# S32K148 register map
Vendor: NXP; Series: S32K; File version: 1.6
CPU: CM4 r0p1, little endian, MPU, FPU, 4 interrupt priority bits
Registers are 32-bit, read-write, reset 0x0 unless marked. A register's access mark holds for its fields unless they carry their own. Offsets are from the block's base; [hi:lo] are bit positions; {n}, {i} and the like mark numbered series; 'fields as' and 'values as' point back to an identical list.

## AIPS — AIPS-Lite Bridge
Base 0x40000000; register names take the prefix AIPS_
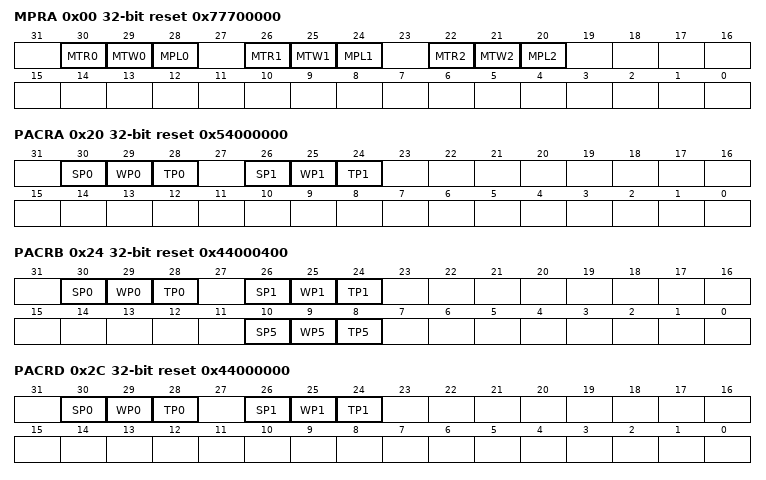
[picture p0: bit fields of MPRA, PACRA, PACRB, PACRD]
0x00 MPRA reset 0x77700000 — Master Privilege Register A
  [30] MTR0 — Master 0 Trusted For Read
    0=This master is not trusted for read accesses; 1=This master is trusted for read accesses
  [29] MTW0 — Master 0 Trusted For Writes
    0=This master is not trusted for write accesses; 1=This master is trusted for write accesses
  [28] MPL0 — Master 0 Privilege Level
    0=Accesses from this master are forced to user-mode; 1=Accesses from this master are not forced to user-mode
  [26] MTR1 — Master 1 Trusted for Read
    values as MTR0
  [25] MTW1 — Master 1 Trusted for Writes
    values as MTW0
  [24] MPL1 — Master 1 Privilege Level
    values as MPL0
  [22] MTR2 — Master 2 Trusted For Read
    values as MTR0
  [21] MTW2 — Master 2 Trusted For Writes
    values as MTW0
  [20] MPL2 — Master 2 Privilege Level
    values as MPL0
0x20 PACRA reset 0x54000000 — Peripheral Access Control Register
  [30] SP0 — Supervisor Protect
    0=This peripheral does not require supervisor privilege level for accesses; 1=This peripheral requires supervisor privilege level for accesses
  [29] WP0 — Write Protect
    0=This peripheral allows write accesses; 1=This peripheral is write protected
  [28] TP0 — Trusted Protect
    0=Accesses from an untrusted master are allowed; 1=Accesses from an untrusted master are not allowed
  [26] SP1 — Supervisor Protect
    values as SP0
  [25] WP1 — Write Protect
    values as WP0
  [24] TP1 — Trusted Protect
    values as TP0
0x24 PACRB reset 0x44000400 — Peripheral Access Control Register
  [30] SP0 — Supervisor Protect
    values as PACRA.SP0
  [29] WP0 — Write Protect
    values as PACRA.WP0
  [28] TP0 — Trusted Protect
    values as PACRA.TP0
  [26] SP1 — Supervisor Protect
    values as PACRA.SP0
  [25] WP1 — Write Protect
    values as PACRA.WP0
  [24] TP1 — Trusted Protect
    values as PACRA.TP0
  [10] SP5 — Supervisor Protect
    values as PACRA.SP0
  [9] WP5 — Write Protect
    values as PACRA.WP0
  [8] TP5 — Trusted Protect
    values as PACRA.TP0
0x28 PACRC ro — Peripheral Access Control Register
0x2C PACRD reset 0x44000000 — Peripheral Access Control Register
  fields as PACRA
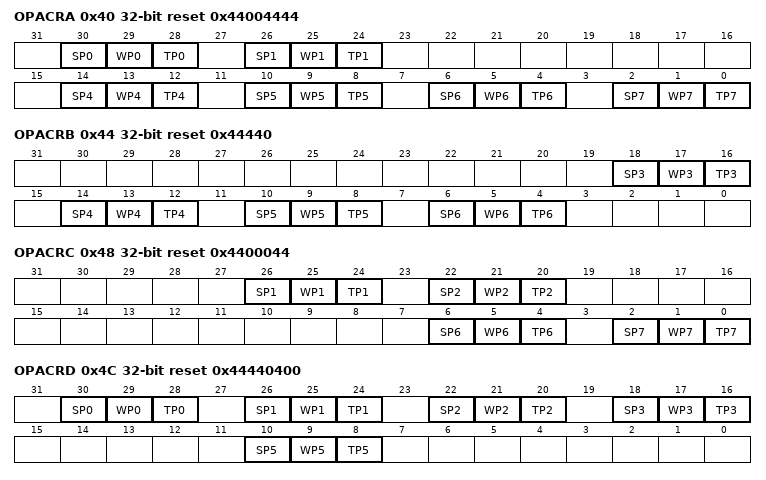
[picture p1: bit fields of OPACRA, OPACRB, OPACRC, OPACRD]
0x40 OPACRA reset 0x44004444 — Off-Platform Peripheral Access Control Register
  [30] SP0 — Supervisor Protect
    values as PACRA.SP0
  [29] WP0 — Write Protect
    values as PACRA.WP0
  [28] TP0 — Trusted Protect
    values as PACRA.TP0
  [26] SP1 — Supervisor Protect
    values as PACRA.SP0
  [25] WP1 — Write Protect
    values as PACRA.WP0
  [24] TP1 — Trusted Protect
    values as PACRA.TP0
  [30-4n] SP{n} (n=4..7) — Supervisor Protect
    values as PACRA.SP0
  [29-4n] WP{n} (n=4..7) — Write Protect
    values as PACRA.WP0
  [28-4n] TP{n} (n=4..7) — Trusted Protect
    values as PACRA.TP0
0x44 OPACRB reset 0x44440 — Off-Platform Peripheral Access Control Register
  [30-4n] SP{n} (n=3..6) — Supervisor Protect
    values as PACRA.SP0
  [29-4n] WP{n} (n=3..6) — Write Protect
    values as PACRA.WP0
  [28-4n] TP{n} (n=3..6) — Trusted Protect
    values as PACRA.TP0
0x48 OPACRC reset 0x4400044 — Off-Platform Peripheral Access Control Register
  [26] SP1 — Supervisor Protect
    values as PACRA.SP0
  [25] WP1 — Write Protect
    values as PACRA.WP0
  [24] TP1 — Trusted Protect
    values as PACRA.TP0
  [22] SP2 — Supervisor Protect
    values as PACRA.SP0
  [21] WP2 — Write Protect
    values as PACRA.WP0
  [20] TP2 — Trusted Protect
    values as PACRA.TP0
  [6] SP6 — Supervisor Protect
    values as PACRA.SP0
  [5] WP6 — Write Protect
    values as PACRA.WP0
  [4] TP6 — Trusted Protect
    values as PACRA.TP0
  [2] SP7 — Supervisor Protect
    values as PACRA.SP0
  [1] WP7 — Write Protect
    values as PACRA.WP0
  [0] TP7 — Trusted Protect
    values as PACRA.TP0
0x4C OPACRD reset 0x44440400 — Off-Platform Peripheral Access Control Register
  [30-4n] SP{n} (n=0..3) — Supervisor Protect
    values as PACRA.SP0
  [29-4n] WP{n} (n=0..3) — Write Protect
    values as PACRA.WP0
  [28-4n] TP{n} (n=0..3) — Trusted Protect
    values as PACRA.TP0
  [10] SP5 — Supervisor Protect
    values as PACRA.SP0
  [9] WP5 — Write Protect
    values as PACRA.WP0
  [8] TP5 — Trusted Protect
    values as PACRA.TP0
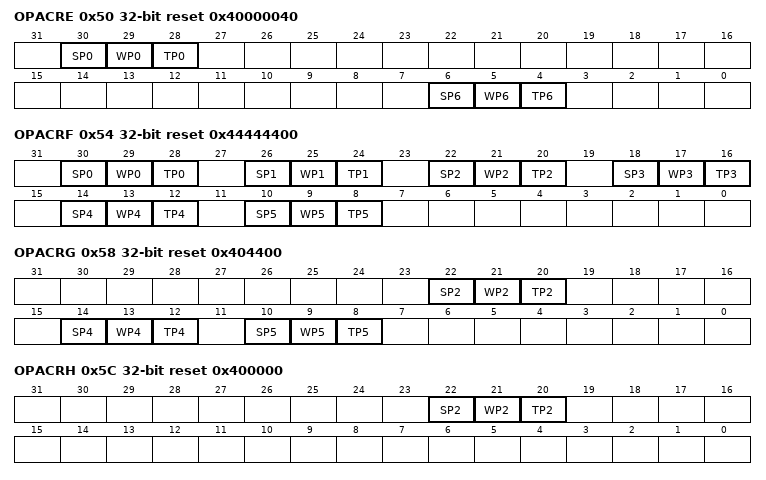
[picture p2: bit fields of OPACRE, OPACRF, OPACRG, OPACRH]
0x50 OPACRE reset 0x40000040 — Off-Platform Peripheral Access Control Register
  [30] SP0 — Supervisor Protect
    values as PACRA.SP0
  [29] WP0 — Write Protect
    values as PACRA.WP0
  [28] TP0 — Trusted Protect
    values as PACRA.TP0
  [6] SP6 — Supervisor Protect
    values as PACRA.SP0
  [5] WP6 — Write Protect
    values as PACRA.WP0
  [4] TP6 — Trusted Protect
    values as PACRA.TP0
0x54 OPACRF reset 0x44444400 — Off-Platform Peripheral Access Control Register
  [30-4n] SP{n} (n=0..5) — Supervisor Protect
    values as PACRA.SP0
  [29-4n] WP{n} (n=0..5) — Write Protect
    values as PACRA.WP0
  [28-4n] TP{n} (n=0..5) — Trusted Protect
    values as PACRA.TP0
0x58 OPACRG reset 0x404400 — Off-Platform Peripheral Access Control Register
  [22] SP2 — Supervisor Protect
    values as PACRA.SP0
  [21] WP2 — Write Protect
    values as PACRA.WP0
  [20] TP2 — Trusted Protect
    values as PACRA.TP0
  [14] SP4 — Supervisor Protect
    values as PACRA.SP0
  [13] WP4 — Write Protect
    values as PACRA.WP0
  [12] TP4 — Trusted Protect
    values as PACRA.TP0
  [10] SP5 — Supervisor Protect
    values as PACRA.SP0
  [9] WP5 — Write Protect
    values as PACRA.WP0
  [8] TP5 — Trusted Protect
    values as PACRA.TP0
0x5C OPACRH reset 0x400000 — Off-Platform Peripheral Access Control Register
  [22] SP2 — Supervisor Protect
    values as PACRA.SP0
  [21] WP2 — Write Protect
    values as PACRA.WP0
  [20] TP2 — Trusted Protect
    values as PACRA.TP0
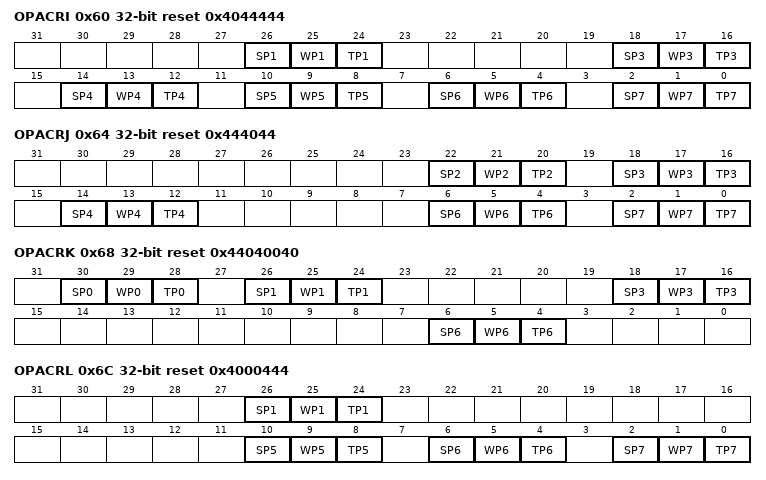
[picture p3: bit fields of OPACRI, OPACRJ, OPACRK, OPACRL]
0x60 OPACRI reset 0x4044444 — Off-Platform Peripheral Access Control Register
  [26] SP1 — Supervisor Protect
    values as PACRA.SP0
  [25] WP1 — Write Protect
    values as PACRA.WP0
  [24] TP1 — Trusted Protect
    values as PACRA.TP0
  [30-4n] SP{n} (n=3..7) — Supervisor Protect
    values as PACRA.SP0
  [29-4n] WP{n} (n=3..7) — Write Protect
    values as PACRA.WP0
  [28-4n] TP{n} (n=3..7) — Trusted Protect
    values as PACRA.TP0
0x64 OPACRJ reset 0x444044 — Off-Platform Peripheral Access Control Register
  [22] SP2 — Supervisor Protect
    values as PACRA.SP0
  [21] WP2 — Write Protect
    values as PACRA.WP0
  [20] TP2 — Trusted Protect
    values as PACRA.TP0
  [18] SP3 — Supervisor Protect
    values as PACRA.SP0
  [17] WP3 — Write Protect
    values as PACRA.WP0
  [16] TP3 — Trusted Protect
    values as PACRA.TP0
  [14] SP4 — Supervisor Protect
    values as PACRA.SP0
  [13] WP4 — Write Protect
    values as PACRA.WP0
  [12] TP4 — Trusted Protect
    values as PACRA.TP0
  [6] SP6 — Supervisor Protect
    values as PACRA.SP0
  [5] WP6 — Write Protect
    values as PACRA.WP0
  [4] TP6 — Trusted Protect
    values as PACRA.TP0
  [2] SP7 — Supervisor Protect
    values as PACRA.SP0
  [1] WP7 — Write Protect
    values as PACRA.WP0
  [0] TP7 — Trusted Protect
    values as PACRA.TP0
0x68 OPACRK reset 0x44040040 — Off-Platform Peripheral Access Control Register
  [30] SP0 — Supervisor Protect
    values as PACRA.SP0
  [29] WP0 — Write Protect
    values as PACRA.WP0
  [28] TP0 — Trusted Protect
    values as PACRA.TP0
  [26] SP1 — Supervisor Protect
    values as PACRA.SP0
  [25] WP1 — Write Protect
    values as PACRA.WP0
  [24] TP1 — Trusted Protect
    values as PACRA.TP0
  [18] SP3 — Supervisor Protect
    values as PACRA.SP0
  [17] WP3 — Write Protect
    values as PACRA.WP0
  [16] TP3 — Trusted Protect
    values as PACRA.TP0
  [6] SP6 — Supervisor Protect
    values as PACRA.SP0
  [5] WP6 — Write Protect
    values as PACRA.WP0
  [4] TP6 — Trusted Protect
    values as PACRA.TP0
0x6C OPACRL reset 0x4000444 — Off-Platform Peripheral Access Control Register
  [26] SP1 — Supervisor Protect
    values as PACRA.SP0
  [25] WP1 — Write Protect
    values as PACRA.WP0
  [24] TP1 — Trusted Protect
    values as PACRA.TP0
  [10] SP5 — Supervisor Protect
    values as PACRA.SP0
  [9] WP5 — Write Protect
    values as PACRA.WP0
  [8] TP5 — Trusted Protect
    values as PACRA.TP0
  [6] SP6 — Supervisor Protect
    values as PACRA.SP0
  [5] WP6 — Write Protect
    values as PACRA.WP0
  [4] TP6 — Trusted Protect
    values as PACRA.TP0
  [2] SP7 — Supervisor Protect
    values as PACRA.SP0
  [1] WP7 — Write Protect
    values as PACRA.WP0
  [0] TP7 — Trusted Protect
    values as PACRA.TP0

## Notices in the file
Redistribution and use in source and binary forms, with or without modification,
are permitted provided that the following conditions are met:
o Redistributions of source code must retain the above copyright notice, this list
of conditions and the following disclaimer.
o Redistributions in binary form must reproduce the above copyright notice, this
list of conditions and the following disclaimer in the documentation and/or
other materials provided with the distribution.
o Neither the name of Freescale Semiconductor, Inc. nor the names of its
contributors may be used to endorse or promote products derived from this
software without specific prior written permission.
THIS SOFTWARE IS PROVIDED BY THE COPYRIGHT HOLDERS AND CONTRIBUTORS "AS IS" AND
ANY EXPRESS OR IMPLIED WARRANTIES, INCLUDING, BUT NOT LIMITED TO, THE IMPLIED
WARRANTIES OF MERCHANTABILITY AND FITNESS FOR A PARTICULAR PURPOSE ARE
DISCLAIMED. IN NO EVENT SHALL THE COPYRIGHT HOLDER OR CONTRIBUTORS BE LIABLE FOR
ANY DIRECT, INDIRECT, INCIDENTAL, SPECIAL, EXEMPLARY, OR CONSEQUENTIAL DAMAGES
(INCLUDING, BUT NOT LIMITED TO, PROCUREMENT OF SUBSTITUTE GOODS OR SERVICES;
LOSS OF USE, DATA, OR PROFITS; OR BUSINESS INTERRUPTION) HOWEVER CAUSED AND ON
ANY THEORY OF LIABILITY, WHETHER IN CONTRACT, STRICT LIABILITY, OR TORT
(INCLUDING NEGLIGENCE OR OTHERWISE) ARISING IN ANY WAY OUT OF THE USE OF THIS
SOFTWARE, EVEN IF ADVISED OF THE POSSIBILITY OF SUCH DAMAGE.
